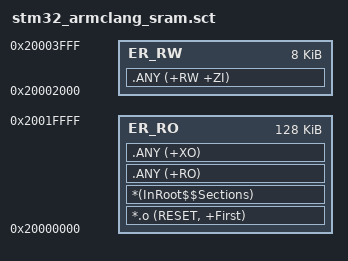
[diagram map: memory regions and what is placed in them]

LR 0x20000000 0x00020000  {       ; load region size_region
  ER_RO 0x20000000 0x00020000  {  ; load address = execution address
   *.o (RESET, +First)
   *(InRoot$$Sections)
   .ANY (+RO)
   .ANY (+XO)
  }
  ER_RW 0x20002000 0x00002000  {  ; RW data
   .ANY (+RW +ZI)
  }
}
